# SYSCTRL_PADCONF_WKUP register map
Vendor: Texas Instruments
Peripheral module from a debugger description file (folder omap4430).
Registers are 32-bit, access per field, reset 0x0 unless marked. A register's access mark holds for its fields unless they carry their own. Offsets are as the file gives them; lines under a group give offsets from that group; [hi:lo] are bit positions; {n}, {i} and the like mark numbered series; 'fields as' and 'values as' point back to an identical list; <NAME> marks a mode.

## SYSCTRL_PADCONF_WKUP
0x00 CONTROL_PADCONF_WKUP_REVISION ro reset not defined — Control module revision identifier Access conditions. Read: unrestricted, Write: unrestricted
  [31:0] REVISION — IP Revision
0x04 CONTROL_PADCONF_WKUP_HWINFO ro — Information about the IP module hardware configuration that is, typically the module HDL generics (if any). Access conditions. Read: unrestricted, Write: unrestricted
  [31:0] IP_HWINFO — IP-module dependent
0x10 CONTROL_PADCONF_WKUP_SYSCONFIG reset 0x8 — Access conditions. Read: unrestricted, Write: unrestricted
  [3:2] IP_SYSCONFIG_IDLEMODE rw — Select the local clock-gating strategy0x2,0x3: Clock is automatically gated when there is no access to the Control Module through L4-interconnect .
    0=Clock is manually gated; 1=Clock is manually enabled
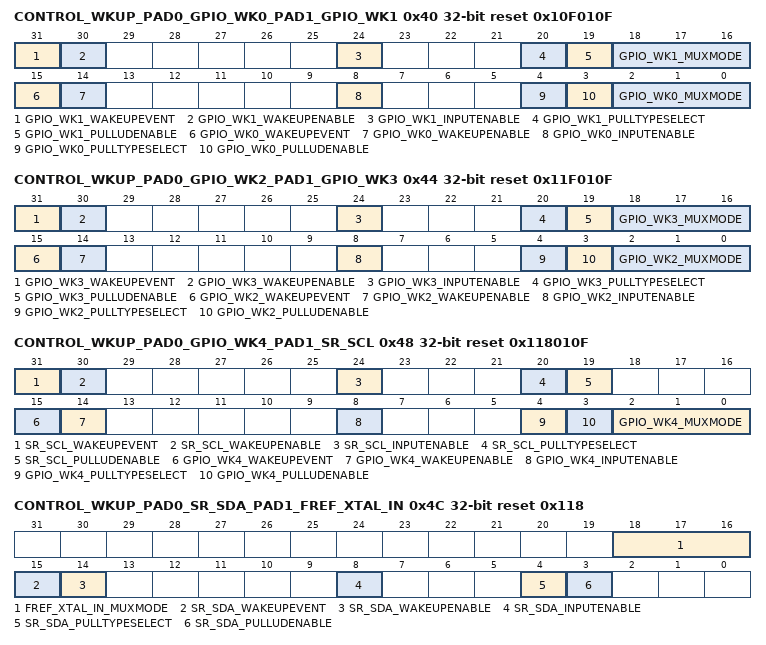
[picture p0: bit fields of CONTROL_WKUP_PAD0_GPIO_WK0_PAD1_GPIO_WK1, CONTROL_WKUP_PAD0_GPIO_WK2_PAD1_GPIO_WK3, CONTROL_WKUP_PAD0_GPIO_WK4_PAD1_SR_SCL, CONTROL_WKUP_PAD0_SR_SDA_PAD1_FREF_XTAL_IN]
0x40 CONTROL_WKUP_PAD0_GPIO_WK0_PAD1_GPIO_WK1 reset 0x10F010F — Register control for Pads gpio_wk0 and gpio_wk1 Access conditions. Read: unrestricted, Write: unrestricted
  [31] GPIO_WK1_WAKEUPEVENT ro — Pad_x wake-up event status latched in the IO
    0=GPIO_WK1_WAKEUPEVENT_0_r (No wake-up event occurred); 1=GPIO_WK1_WAKEUPEVENT_1_r (A wake-up event occurred)
  [30] GPIO_WK1_WAKEUPENABLE rw — Input pad wake-up enable (and OFF mode input enable value)
    0=wake-up detection is disabled; 1=wake-up detection is enabled
  [24] GPIO_WK1_INPUTENABLE rw — Input enable value for pad gpio_wk1
    0=Input buffer of I/O cell is disabled; 1=Input buffer of I/O cell is enabled
  [20] GPIO_WK1_PULLTYPESELECT rw — pullup/down selection for pad gpio_wk1
    0=pulldown selected; 1=pullup selected
  [19] GPIO_WK1_PULLUDENABLE rw — pullup/down enable for pad gpio_wk1
    0=pullup/down disabled; 1=pullup/down enabled
  [18:16] GPIO_WK1_MUXMODE rw — Functional multiplexing selection for pad gpio_wk1
    3=Select gpio_wk1; 6=Select hw_dbg2; 7=Select safe_mode
  [15] GPIO_WK0_WAKEUPEVENT ro — Pad_x wake-up event status latched in the IO
    0=GPIO_WK0_WAKEUPEVENT_0_r (No wake-up event occurred); 1=GPIO_WK0_WAKEUPEVENT_1_r (A wake-up event occurred)
  [14] GPIO_WK0_WAKEUPENABLE rw — Input pad wake-up enable (and OFF mode input enable value)
    values as GPIO_WK1_WAKEUPENABLE
  [8] GPIO_WK0_INPUTENABLE rw — Input enable value for pad gpio_wk0
    values as GPIO_WK1_INPUTENABLE
  [4] GPIO_WK0_PULLTYPESELECT rw — pullup/down selection for pad gpio_wk0
    0=pulldown selected; 1=pullup selected
  [3] GPIO_WK0_PULLUDENABLE rw — pullup/down enable for pad gpio_wk0
    0=pullup/down disabled; 1=pullup/down enabled
  [2:0] GPIO_WK0_MUXMODE rw — Functional multiplexing selection for pad gpio_wk0
    3=Select gpio_wk0; 6=Select hw_dbg1; 7=Select safe_mode
0x44 CONTROL_WKUP_PAD0_GPIO_WK2_PAD1_GPIO_WK3 reset 0x11F010F — Register control for Pads gpio_wk2 and gpio_wk3 Access conditions. Read: unrestricted, Write: unrestricted
  [31] GPIO_WK3_WAKEUPEVENT ro — Pad_x wake-up event status latched in the IO
    0=GPIO_WK3_WAKEUPEVENT_0_r (No wake-up event occurred); 1=GPIO_WK3_WAKEUPEVENT_1_r (A wake-up event occurred)
  [30] GPIO_WK3_WAKEUPENABLE rw — Input pad wake-up enable (and OFF mode input enable value)
    values as CONTROL_WKUP_PAD0_GPIO_WK0_PAD1_GPIO_WK1.GPIO_WK1_WAKEUPENABLE
  [24] GPIO_WK3_INPUTENABLE rw — Input enable value for pad gpio_wk3
    values as CONTROL_WKUP_PAD0_GPIO_WK0_PAD1_GPIO_WK1.GPIO_WK1_INPUTENABLE
  [20] GPIO_WK3_PULLTYPESELECT rw — pullup/down selection for pad gpio_wk3
    0=pulldown selected; 1=pullup selected
  [19] GPIO_WK3_PULLUDENABLE rw — pullup/down enable for pad gpio_wk3
    0=pullup/down disabled; 1=pullup/down enabled
  [18:16] GPIO_WK3_MUXMODE rw — Functional multiplexing selection for pad gpio_wk3
    3=Select gpio_wk3; 6=Select hw_dbg4; 7=Select safe_mode
  [15] GPIO_WK2_WAKEUPEVENT ro — Pad_x wake-up event status latched in the IO
    0=GPIO_WK2_WAKEUPEVENT_0_r (No wake-up event occurred); 1=GPIO_WK2_WAKEUPEVENT_1_r (A wake-up event occurred)
  [14] GPIO_WK2_WAKEUPENABLE rw — Input pad wake-up enable (and OFF mode input enable value)
    values as CONTROL_WKUP_PAD0_GPIO_WK0_PAD1_GPIO_WK1.GPIO_WK1_WAKEUPENABLE
  [8] GPIO_WK2_INPUTENABLE rw — Input enable value for pad gpio_wk2
    values as CONTROL_WKUP_PAD0_GPIO_WK0_PAD1_GPIO_WK1.GPIO_WK1_INPUTENABLE
  [4] GPIO_WK2_PULLTYPESELECT rw — pullup/down selection for pad gpio_wk2
    0=pulldown selected; 1=pullup selected
  [3] GPIO_WK2_PULLUDENABLE rw — pullup/down enable for pad gpio_wk2
    0=pullup/down disabled; 1=pullup/down enabled
  [2:0] GPIO_WK2_MUXMODE rw — Functional multiplexing selection for pad gpio_wk2
    3=Select gpio_wk2; 6=Select hw_dbg3; 7=Select safe_mode
0x48 CONTROL_WKUP_PAD0_GPIO_WK4_PAD1_SR_SCL reset 0x118010F — Register control for Pads gpio_wk4 and sr_scl Access conditions. Read: unrestricted, Write: unrestricted
  [31] SR_SCL_WAKEUPEVENT ro — Pad_x wake-up event status latched in the IO
    0=SR_SCL_WAKEUPEVENT_0_r (No wake-up event occurred); 1=SR_SCL_WAKEUPEVENT_1_r (A wake-up event occurred)
  [30] SR_SCL_WAKEUPENABLE rw — Input pad wake-up enable (and OFF mode input enable value)
    values as CONTROL_WKUP_PAD0_GPIO_WK0_PAD1_GPIO_WK1.GPIO_WK1_WAKEUPENABLE
  [24] SR_SCL_INPUTENABLE rw — Input enable value for pad sr_scl
    values as CONTROL_WKUP_PAD0_GPIO_WK0_PAD1_GPIO_WK1.GPIO_WK1_INPUTENABLE
  [20] SR_SCL_PULLTYPESELECT rw — pullup/down selection for pad sr_scl
    0=pulldown selected; 1=pullup selected
  [19] SR_SCL_PULLUDENABLE rw — pullup/down enable for pad sr_scl
    0=pullup/down disabled; 1=pullup/down enabled
  [15] GPIO_WK4_WAKEUPEVENT ro — Pad_x wake-up event status latched in the IO
    0=GPIO_WK4_WAKEUPEVENT_0_r (No wake-up event occurred); 1=GPIO_WK4_WAKEUPEVENT_1_r (A wake-up event occurred)
  [14] GPIO_WK4_WAKEUPENABLE rw — Input pad wake-up enable (and OFF mode input enable value)
    values as CONTROL_WKUP_PAD0_GPIO_WK0_PAD1_GPIO_WK1.GPIO_WK1_WAKEUPENABLE
  [8] GPIO_WK4_INPUTENABLE rw — Input enable value for pad gpio_wk4
    values as CONTROL_WKUP_PAD0_GPIO_WK0_PAD1_GPIO_WK1.GPIO_WK1_INPUTENABLE
  [4] GPIO_WK4_PULLTYPESELECT rw — pullup/down selection for pad gpio_wk4
    0=pulldown selected; 1=pullup selected
  [3] GPIO_WK4_PULLUDENABLE rw — pullup/down enable for pad gpio_wk4
    0=pullup/down disabled; 1=pullup/down enabled
  [2:0] GPIO_WK4_MUXMODE rw — Functional multiplexing selection for pad gpio_wk4
    3=Select gpio_wk4; 6=Select hw_dbg5; 7=Select safe_mode
0x4C CONTROL_WKUP_PAD0_SR_SDA_PAD1_FREF_XTAL_IN reset 0x118 — Register control for Pads sr_sda and fref_xtal_in Access conditions. Read: unrestricted, Write: unrestricted
  [18:16] FREF_XTAL_IN_MUXMODE rw — Functional multiplexing selection for pad fref_xtal_in
    0=Select fref_xtal_in; 4=Select c2c_wakereqin
  [15] SR_SDA_WAKEUPEVENT ro — Pad_x wake-up event status latched in the IO
    0=SR_SDA_WAKEUPEVENT_0_r (No wake-up event occurred); 1=SR_SDA_WAKEUPEVENT_1_r (A wake-up event occurred)
  [14] SR_SDA_WAKEUPENABLE rw — Input pad wake-up enable (and OFF mode input enable value)
    values as CONTROL_WKUP_PAD0_GPIO_WK0_PAD1_GPIO_WK1.GPIO_WK1_WAKEUPENABLE
  [8] SR_SDA_INPUTENABLE rw — Input enable value for pad sr_sda
    values as CONTROL_WKUP_PAD0_GPIO_WK0_PAD1_GPIO_WK1.GPIO_WK1_INPUTENABLE
  [4] SR_SDA_PULLTYPESELECT rw — pullup/down selection for pad sr_sda
    0=pulldown selected; 1=pullup selected
  [3] SR_SDA_PULLUDENABLE rw — pullup/down enable for pad sr_sda
    0=pullup/down disabled; 1=pullup/down enabled
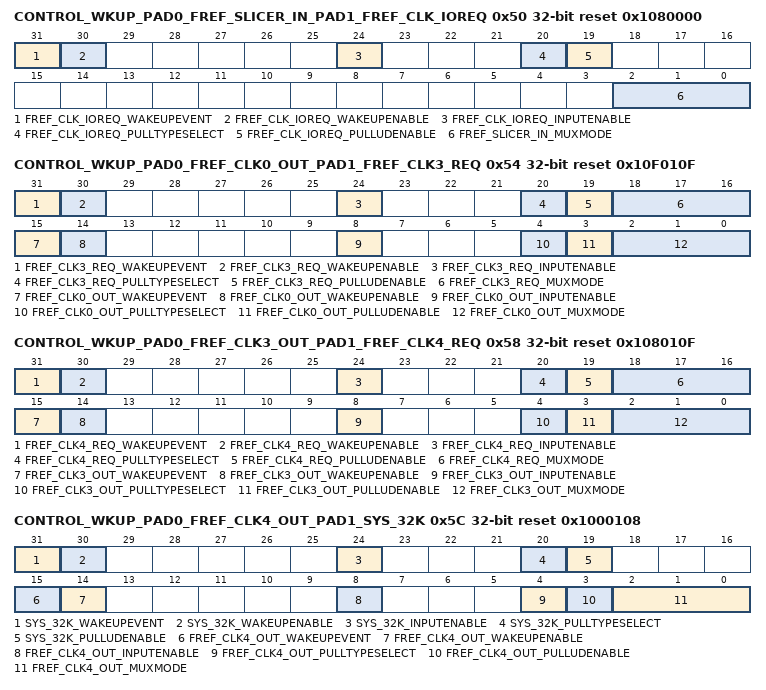
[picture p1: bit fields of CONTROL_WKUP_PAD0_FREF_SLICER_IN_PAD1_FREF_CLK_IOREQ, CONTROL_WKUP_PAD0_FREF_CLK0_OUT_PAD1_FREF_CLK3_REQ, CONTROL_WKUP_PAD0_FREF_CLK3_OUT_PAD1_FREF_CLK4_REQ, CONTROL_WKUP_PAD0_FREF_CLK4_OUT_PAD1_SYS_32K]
0x50 CONTROL_WKUP_PAD0_FREF_SLICER_IN_PAD1_FREF_CLK_IOREQ reset 0x1080000 — Register control for Pads fref_slicer_in and fref_clk_ioreq Access conditions. Read: unrestricted, Write: unrestricted
  [31] FREF_CLK_IOREQ_WAKEUPEVENT ro — Pad_x wake-up event status latched in the IO
    0=FREF_CLK_IOREQ_WAKEUPEVENT_0_r (No wake-up event occurred); 1=FREF_CLK_IOREQ_WAKEUPEVENT_1_r (A wake-up event occurred)
  [30] FREF_CLK_IOREQ_WAKEUPENABLE rw — Input pad wake-up enable (and OFF mode input enable value)
    values as CONTROL_WKUP_PAD0_GPIO_WK0_PAD1_GPIO_WK1.GPIO_WK1_WAKEUPENABLE
  [24] FREF_CLK_IOREQ_INPUTENABLE rw — Input enable value for pad fref_clk_ioreq
    values as CONTROL_WKUP_PAD0_GPIO_WK0_PAD1_GPIO_WK1.GPIO_WK1_INPUTENABLE
  [20] FREF_CLK_IOREQ_PULLTYPESELECT rw — pullup/down selection for pad fref_clk_ioreq
    0=pulldown selected; 1=pullup selected
  [19] FREF_CLK_IOREQ_PULLUDENABLE rw — pullup/down enable for pad fref_clk_ioreq
    0=pullup/down disabled; 1=pullup/down enabled
  [2:0] FREF_SLICER_IN_MUXMODE rw — Functional multiplexing selection for pad fref_slicer_in
    0=Select fref_slicer_in; 3=Select gpi_wk5; 4=Select c2c_wakereqin; 7=Select safe_mode
0x54 CONTROL_WKUP_PAD0_FREF_CLK0_OUT_PAD1_FREF_CLK3_REQ reset 0x10F010F — Register control for Pads fref_clk0_out and fref_clk3_req Access conditions. Read: unrestricted, Write: unrestricted
  [31] FREF_CLK3_REQ_WAKEUPEVENT ro — Pad_x wake-up event status latched in the IO
    0=FREF_CLK3_REQ_WAKEUPEVENT_0_r (No wake-up event occurred); 1=FREF_CLK3_REQ_WAKEUPEVENT_1_r (A wake-up event occurred)
  [30] FREF_CLK3_REQ_WAKEUPENABLE rw — Input pad wake-up enable (and OFF mode input enable value)
    values as CONTROL_WKUP_PAD0_GPIO_WK0_PAD1_GPIO_WK1.GPIO_WK1_WAKEUPENABLE
  [24] FREF_CLK3_REQ_INPUTENABLE rw — Input enable value for pad fref_clk3_req
    values as CONTROL_WKUP_PAD0_GPIO_WK0_PAD1_GPIO_WK1.GPIO_WK1_INPUTENABLE
  [20] FREF_CLK3_REQ_PULLTYPESELECT rw — pullup/down selection for pad fref_clk3_req
    0=pulldown selected; 1=pullup selected
  [19] FREF_CLK3_REQ_PULLUDENABLE rw — pullup/down enable for pad fref_clk3_req
    0=pullup/down disabled; 1=pullup/down enabled
  [18:16] FREF_CLK3_REQ_MUXMODE rw — Functional multiplexing selection for pad fref_clk3_req
    0=Select fref_clk3_req; 1=Select fref_clk1_req; 3=Select gpio_wk30; 4=Select c2c_wakereqin; 5=Select sdmmc2_dat4; 6=Select hw_dbg7; 7=Select safe_mode
  [15] FREF_CLK0_OUT_WAKEUPEVENT ro — Pad_x wake-up event status latched in the IO
    0=FREF_CLK0_OUT_WAKEUPEVENT_0_r (No wake-up event occurred); 1=FREF_CLK0_OUT_WAKEUPEVENT_1_r (A wake-up event occurred)
  [14] FREF_CLK0_OUT_WAKEUPENABLE rw — Input pad wake-up enable (and OFF mode input enable value)
    values as CONTROL_WKUP_PAD0_GPIO_WK0_PAD1_GPIO_WK1.GPIO_WK1_WAKEUPENABLE
  [8] FREF_CLK0_OUT_INPUTENABLE rw — Input enable value for pad fref_clk0_out
    values as CONTROL_WKUP_PAD0_GPIO_WK0_PAD1_GPIO_WK1.GPIO_WK1_INPUTENABLE
  [4] FREF_CLK0_OUT_PULLTYPESELECT rw — pullup/down selection for pad fref_clk0_out
    0=pulldown selected; 1=pullup selected
  [3] FREF_CLK0_OUT_PULLUDENABLE rw — pullup/down enable for pad fref_clk0_out
    0=pullup/down disabled; 1=pullup/down enabled
  [2:0] FREF_CLK0_OUT_MUXMODE rw — Functional multiplexing selection for pad fref_clk0_out
    0=Select fref_clk0_out; 1=Select fref_clk1_req; 3=Select gpio_wk6; 5=Select sdmmc2_dat7; 6=Select hw_dbg6; 7=Select safe_mode
0x58 CONTROL_WKUP_PAD0_FREF_CLK3_OUT_PAD1_FREF_CLK4_REQ reset 0x108010F — Register control for Pads fref_clk3_out and fref_clk4_req Access conditions. Read: unrestricted, Write: unrestricted
  [31] FREF_CLK4_REQ_WAKEUPEVENT ro — Pad_x wake-up event status latched in the IO
    0=FREF_CLK4_REQ_WAKEUPEVENT_0_r (No wake-up event occurred); 1=FREF_CLK4_REQ_WAKEUPEVENT_1_r (A wake-up event occurred)
  [30] FREF_CLK4_REQ_WAKEUPENABLE rw — Input pad wake-up enable (and OFF mode input enable value)
    values as CONTROL_WKUP_PAD0_GPIO_WK0_PAD1_GPIO_WK1.GPIO_WK1_WAKEUPENABLE
  [24] FREF_CLK4_REQ_INPUTENABLE rw — Input enable value for pad fref_clk4_req
    values as CONTROL_WKUP_PAD0_GPIO_WK0_PAD1_GPIO_WK1.GPIO_WK1_INPUTENABLE
  [20] FREF_CLK4_REQ_PULLTYPESELECT rw — pullup/down selection for pad fref_clk4_req
    0=pulldown selected; 1=pullup selected
  [19] FREF_CLK4_REQ_PULLUDENABLE rw — pullup/down enable for pad fref_clk4_req
    0=pullup/down disabled; 1=pullup/down enabled
  [18:16] FREF_CLK4_REQ_MUXMODE rw — Functional multiplexing selection for pad fref_clk4_req
    0=Select fref_clk4_req; 1=Select fref_clk5_out; 3=Select gpio_wk7; 5=Select sdmmc2_dat6; 6=Select hw_dbg9
  [15] FREF_CLK3_OUT_WAKEUPEVENT ro — Pad_x wake-up event status latched in the IO
    0=FREF_CLK3_OUT_WAKEUPEVENT_0_r (No wake-up event occurred); 1=FREF_CLK3_OUT_WAKEUPEVENT_1_r (A wake-up event occurred)
  [14] FREF_CLK3_OUT_WAKEUPENABLE rw — Input pad wake-up enable (and OFF mode input enable value)
    values as CONTROL_WKUP_PAD0_GPIO_WK0_PAD1_GPIO_WK1.GPIO_WK1_WAKEUPENABLE
  [8] FREF_CLK3_OUT_INPUTENABLE rw — Input enable value for pad fref_clk3_out
    values as CONTROL_WKUP_PAD0_GPIO_WK0_PAD1_GPIO_WK1.GPIO_WK1_INPUTENABLE
  [4] FREF_CLK3_OUT_PULLTYPESELECT rw — pullup/down selection for pad fref_clk3_out
    0=pulldown selected; 1=pullup selected
  [3] FREF_CLK3_OUT_PULLUDENABLE rw — pullup/down enable for pad fref_clk3_out
    0=pullup/down disabled; 1=pullup/down enabled
  [2:0] FREF_CLK3_OUT_MUXMODE rw — Functional multiplexing selection for pad fref_clk3_out
    0=Select fref_clk3_out; 1=Select fref_clk2_req; 3=Select gpio_wk31; 4=Select c2c_wakereqout; 5=Select sdmmc2_dat5; 6=Select hw_dbg8; 7=Select safe_mode
0x5C CONTROL_WKUP_PAD0_FREF_CLK4_OUT_PAD1_SYS_32K reset 0x1000108 — Register control for Pads fref_clk4_out and sys_32k Access conditions. Read: unrestricted, Write: unrestricted
  [31] SYS_32K_WAKEUPEVENT ro — Pad_x wake-up event status latched in the IO
    0=SYS_32K_WAKEUPEVENT_0_r (No wake-up event occurred); 1=SYS_32K_WAKEUPEVENT_1_r (A wake-up event occurred)
  [30] SYS_32K_WAKEUPENABLE rw — Input pad wake-up enable (and OFF mode input enable value)
    values as CONTROL_WKUP_PAD0_GPIO_WK0_PAD1_GPIO_WK1.GPIO_WK1_WAKEUPENABLE
  [24] SYS_32K_INPUTENABLE rw — Input enable value for pad sys_32k
    values as CONTROL_WKUP_PAD0_GPIO_WK0_PAD1_GPIO_WK1.GPIO_WK1_INPUTENABLE
  [20] SYS_32K_PULLTYPESELECT rw — pullup/down selection for pad sys_32k
    0=pulldown selected; 1=pullup selected
  [19] SYS_32K_PULLUDENABLE rw — pullup/down enable for pad sys_32k
    0=pullup/down disabled; 1=pullup/down enabled
  [15] FREF_CLK4_OUT_WAKEUPEVENT ro — Pad_x wake-up event status latched in the IO
    0=FREF_CLK4_OUT_WAKEUPEVENT_0_r (No wake-up event occurred); 1=FREF_CLK4_OUT_WAKEUPEVENT_1_r (A wake-up event occurred)
  [14] FREF_CLK4_OUT_WAKEUPENABLE rw — Input pad wake-up enable (and OFF mode input enable value)
    values as CONTROL_WKUP_PAD0_GPIO_WK0_PAD1_GPIO_WK1.GPIO_WK1_WAKEUPENABLE
  [8] FREF_CLK4_OUT_INPUTENABLE rw — Input enable value for pad fref_clk4_out
    values as CONTROL_WKUP_PAD0_GPIO_WK0_PAD1_GPIO_WK1.GPIO_WK1_INPUTENABLE
  [4] FREF_CLK4_OUT_PULLTYPESELECT rw — pullup/down selection for pad fref_clk4_out
    0=pulldown selected; 1=pullup selected
  [3] FREF_CLK4_OUT_PULLUDENABLE rw — pullup/down enable for pad fref_clk4_out
    0=pullup/down disabled; 1=pullup/down enabled
  [2:0] FREF_CLK4_OUT_MUXMODE rw — Functional multiplexing selection for pad fref_clk4_out
    0=Select fref_clk4_out; 3=Select gpio_wk8; 6=Select hw_dbg10
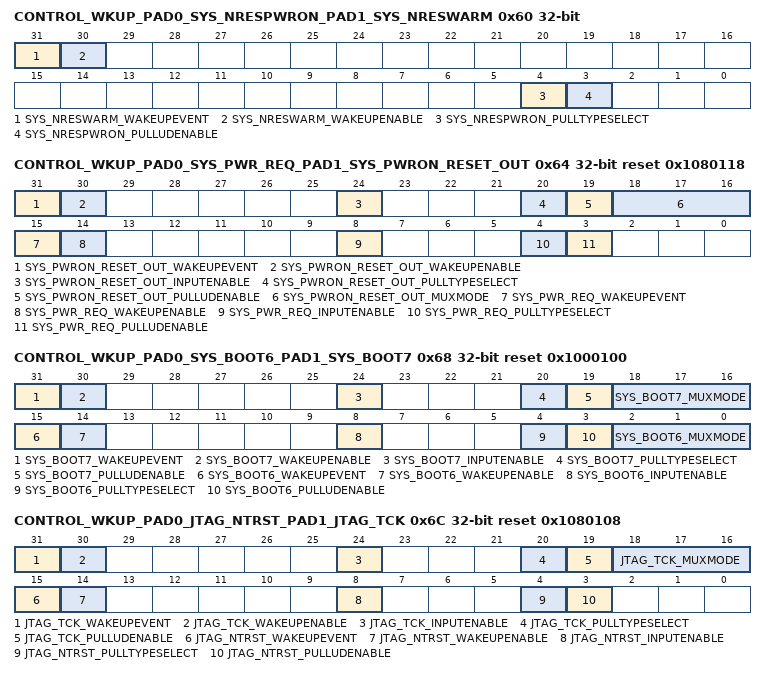
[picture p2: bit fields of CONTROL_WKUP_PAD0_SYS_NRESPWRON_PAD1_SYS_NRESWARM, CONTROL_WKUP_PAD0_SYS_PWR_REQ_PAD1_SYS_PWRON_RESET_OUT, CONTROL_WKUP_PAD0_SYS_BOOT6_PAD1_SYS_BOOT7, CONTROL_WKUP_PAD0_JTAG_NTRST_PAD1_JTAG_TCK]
0x60 CONTROL_WKUP_PAD0_SYS_NRESPWRON_PAD1_SYS_NRESWARM — Register control for Pads sys_nrespwron and sys_nreswarm Access conditions. Read: unrestricted, Write: unrestricted
  [31] SYS_NRESWARM_WAKEUPEVENT ro — Pad_x wake-up event status latched in the IO
    0=SYS_NRESWARM_WAKEUPEVENT_0_r (No wake-up event occurred); 1=SYS_NRESWARM_WAKEUPEVENT_1_r (A wake-up event occurred)
  [30] SYS_NRESWARM_WAKEUPENABLE rw — Input pad wake-up enable (and OFF mode input enable value)
    values as CONTROL_WKUP_PAD0_GPIO_WK0_PAD1_GPIO_WK1.GPIO_WK1_WAKEUPENABLE
  [4] SYS_NRESPWRON_PULLTYPESELECT rw — pullup/down selection for pad sys_nrespwron
    0=pulldown selected; 1=pullup selected
  [3] SYS_NRESPWRON_PULLUDENABLE rw — pullup/down enable for pad sys_nrespwron
    0=pullup/down disabled; 1=pullup/down enabled
0x64 CONTROL_WKUP_PAD0_SYS_PWR_REQ_PAD1_SYS_PWRON_RESET_OUT reset 0x1080118 — Register control for Pads sys_pwr_req and sys_pwron_reset_out Access conditions. Read: unrestricted, Write: unrestricted
  [31] SYS_PWRON_RESET_OUT_WAKEUPEVENT ro — Pad_x wake-up event status latched in the IO
    0=SYS_PWRON_RESET_OUT_WAKEUPEVENT_0_r (No wake-up event occurred); 1=SYS_PWRON_RESET_OUT_WAKEUPEVENT_1_r (A wake-up event occurred)
  [30] SYS_PWRON_RESET_OUT_WAKEUPENABLE rw — Input pad wake-up enable (and OFF mode input enable value)
    values as CONTROL_WKUP_PAD0_GPIO_WK0_PAD1_GPIO_WK1.GPIO_WK1_WAKEUPENABLE
  [24] SYS_PWRON_RESET_OUT_INPUTENABLE rw — Input enable value for pad sys_pwron_reset_out
    values as CONTROL_WKUP_PAD0_GPIO_WK0_PAD1_GPIO_WK1.GPIO_WK1_INPUTENABLE
  [20] SYS_PWRON_RESET_OUT_PULLTYPESELECT rw — pullup/down selection for pad sys_pwron_reset_out
    0=pulldown selected; 1=pullup selected
  [19] SYS_PWRON_RESET_OUT_PULLUDENABLE rw — pullup/down enable for pad sys_pwron_reset_out
    0=pullup/down disabled; 1=pullup/down enabled
  [18:16] SYS_PWRON_RESET_OUT_MUXMODE rw — Functional multiplexing selection for pad sys_pwron_reset_out
    0=Select sys_pwron_reset_out; 3=Select gpio_wk29; 6=SYS_PWRON_ RESET_OUT_MUXMODE_6 (Select hw_dbg11)
  [15] SYS_PWR_REQ_WAKEUPEVENT ro — Pad_x wake-up event status latched in the IO
    0=SYS_PWR_REQ_WAKEUPEVENT_0_r (No wake-up event occurred); 1=SYS_PWR_REQ_WAKEUPEVENT_1_r (A wake-up event occurred)
  [14] SYS_PWR_REQ_WAKEUPENABLE rw — Input pad wake-up enable (and OFF mode input enable value)
    values as CONTROL_WKUP_PAD0_GPIO_WK0_PAD1_GPIO_WK1.GPIO_WK1_WAKEUPENABLE
  [8] SYS_PWR_REQ_INPUTENABLE rw — Input enable value for pad sys_pwr_req
    values as CONTROL_WKUP_PAD0_GPIO_WK0_PAD1_GPIO_WK1.GPIO_WK1_INPUTENABLE
  [4] SYS_PWR_REQ_PULLTYPESELECT rw — pullup/down selection for pad sys_pwr_req
    0=pulldown selected; 1=pullup selected
  [3] SYS_PWR_REQ_PULLUDENABLE rw — pullup/down enable for pad sys_pwr_req
    0=pullup/down disabled; 1=pullup/down enabled
0x68 CONTROL_WKUP_PAD0_SYS_BOOT6_PAD1_SYS_BOOT7 reset 0x1000100 — Register control for Pads sys_boot6 and sys_boot7 Access conditions. Read: unrestricted, Write: unrestricted
  [31] SYS_BOOT7_WAKEUPEVENT ro — Pad_x wake-up event status latched in the IO
    0=SYS_BOOT7_WAKEUPEVENT_0_r (No wake-up event occurred); 1=SYS_BOOT7_WAKEUPEVENT_1_r (A wake-up event occurred)
  [30] SYS_BOOT7_WAKEUPENABLE rw — Input pad wake-up enable (and OFF mode input enable value)
    values as CONTROL_WKUP_PAD0_GPIO_WK0_PAD1_GPIO_WK1.GPIO_WK1_WAKEUPENABLE
  [24] SYS_BOOT7_INPUTENABLE rw — Input enable value for pad sys_boot7
    values as CONTROL_WKUP_PAD0_GPIO_WK0_PAD1_GPIO_WK1.GPIO_WK1_INPUTENABLE
  [20] SYS_BOOT7_PULLTYPESELECT rw — pullup/down selection for pad sys_boot7
    0=pulldown selected; 1=pullup selected
  [19] SYS_BOOT7_PULLUDENABLE rw — pullup/down enable for pad sys_boot7
    0=pullup/down disabled; 1=pullup/down enabled
  [18:16] SYS_BOOT7_MUXMODE rw — Functional multiplexing selection for pad sys_boot7
    0=Select sys_boot7; 1=Select dpm_emu19; 3=Select gpio_wk10; 6=Select hw_dbg13; 7=Select safe_mode
  [15] SYS_BOOT6_WAKEUPEVENT ro — Pad_x wake-up event status latched in the IO
    0=SYS_BOOT6_WAKEUPEVENT_0_r (No wake-up event occurred); 1=SYS_BOOT6_WAKEUPEVENT_1_r (A wake-up event occurred)
  [14] SYS_BOOT6_WAKEUPENABLE rw — Input pad wake-up enable (and OFF mode input enable value)
    values as CONTROL_WKUP_PAD0_GPIO_WK0_PAD1_GPIO_WK1.GPIO_WK1_WAKEUPENABLE
  [8] SYS_BOOT6_INPUTENABLE rw — Input enable value for pad sys_boot6
    values as CONTROL_WKUP_PAD0_GPIO_WK0_PAD1_GPIO_WK1.GPIO_WK1_INPUTENABLE
  [4] SYS_BOOT6_PULLTYPESELECT rw — pullup/down selection for pad sys_boot6
    0=pulldown selected; 1=pullup selected
  [3] SYS_BOOT6_PULLUDENABLE rw — pullup/down enable for pad sys_boot6
    0=pullup/down disabled; 1=pullup/down enabled
  [2:0] SYS_BOOT6_MUXMODE rw — Functional multiplexing selection for pad sys_boot6
    0=Select sys_boot6; 1=Select dpm_emu18; 3=Select gpio_wk9; 4=Select c2c_wakereqout; 6=Select hw_dbg12; 7=Select safe_mode
0x6C CONTROL_WKUP_PAD0_JTAG_NTRST_PAD1_JTAG_TCK reset 0x1080108 — Register control for Pads jtag_ntrst and jtag_tck Access conditions. Read: unrestricted, Write: unrestricted
  [31] JTAG_TCK_WAKEUPEVENT ro — Pad_x wake-up event status latched in the IO
    0=JTAG_TCK_WAKEUPEVENT_0_r (No wake-up event occurred); 1=JTAG_TCK_WAKEUPEVENT_1_r (A wake-up event occurred)
  [30] JTAG_TCK_WAKEUPENABLE rw — Input pad wake-up enable (and OFF mode input enable value)
    values as CONTROL_WKUP_PAD0_GPIO_WK0_PAD1_GPIO_WK1.GPIO_WK1_WAKEUPENABLE
  [24] JTAG_TCK_INPUTENABLE rw — Input enable value for pad jtag_tck
    values as CONTROL_WKUP_PAD0_GPIO_WK0_PAD1_GPIO_WK1.GPIO_WK1_INPUTENABLE
  [20] JTAG_TCK_PULLTYPESELECT rw — pullup/down selection for pad jtag_tck
    0=pulldown selected; 1=pullup selected
  [19] JTAG_TCK_PULLUDENABLE rw — pullup/down enable for pad jtag_tck
    0=pullup/down disabled; 1=pullup/down enabled
  [18:16] JTAG_TCK_MUXMODE rw — Functional multiplexing selection for pad jtag_tck
    0=Select jtag_tck; 7=Select safe_mode
  [15] JTAG_NTRST_WAKEUPEVENT ro — Pad_x wake-up event status latched in the IO
    0=JTAG_NTRST_WAKEUPEVENT_0_r (No wake-up event occurred); 1=JTAG_NTRST_WAKEUPEVENT_1_r (A wake-up event occurred)
  [14] JTAG_NTRST_WAKEUPENABLE rw — Input pad wake-up enable (and OFF mode input enable value)
    values as CONTROL_WKUP_PAD0_GPIO_WK0_PAD1_GPIO_WK1.GPIO_WK1_WAKEUPENABLE
  [8] JTAG_NTRST_INPUTENABLE rw — Input enable value for pad jtag_ntrst
    values as CONTROL_WKUP_PAD0_GPIO_WK0_PAD1_GPIO_WK1.GPIO_WK1_INPUTENABLE
  [4] JTAG_NTRST_PULLTYPESELECT rw — pullup/down selection for pad jtag_ntrst
    0=pulldown selected; 1=pullup selected
  [3] JTAG_NTRST_PULLUDENABLE rw — pullup/down enable for pad jtag_ntrst
    0=pullup/down disabled; 1=pullup/down enabled
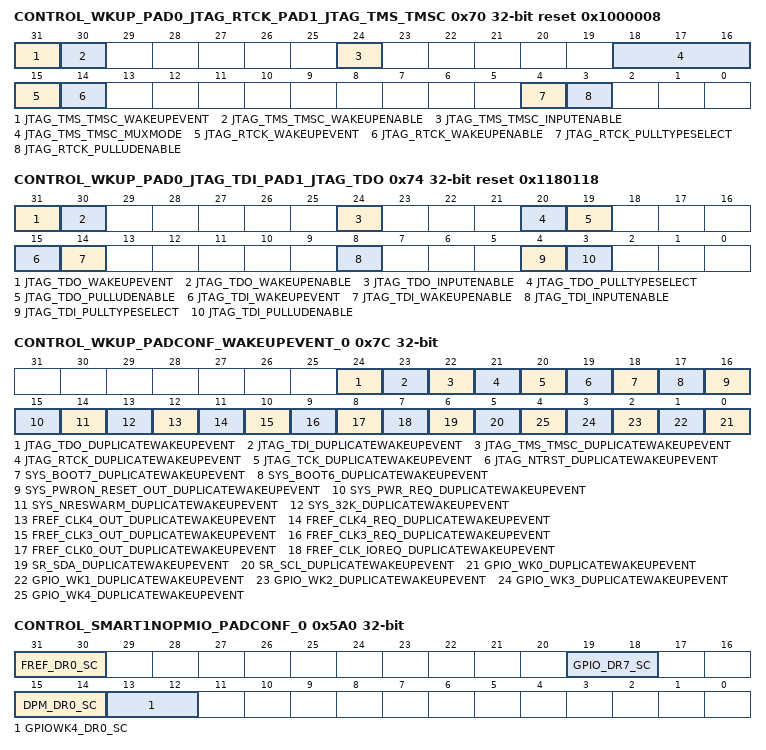
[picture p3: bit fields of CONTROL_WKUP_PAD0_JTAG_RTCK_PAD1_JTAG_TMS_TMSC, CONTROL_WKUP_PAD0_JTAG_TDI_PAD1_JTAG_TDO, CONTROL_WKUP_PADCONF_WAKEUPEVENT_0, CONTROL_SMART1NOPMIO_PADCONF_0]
0x70 CONTROL_WKUP_PAD0_JTAG_RTCK_PAD1_JTAG_TMS_TMSC reset 0x1000008 — Register control for Pads jtag_rtck and jtag_tms_tmsc Access conditions. Read: unrestricted, Write: unrestricted
  [31] JTAG_TMS_TMSC_WAKEUPEVENT ro — Pad_x wake-up event status latched in the IO
    0=JTAG_TMS_TMSC_WAKEUPEVENT_0_r (No wake-up event occurred); 1=JTAG_TMS_TMSC_WAKEUPEVENT_1_r (A wake-up event occurred)
  [30] JTAG_TMS_TMSC_WAKEUPENABLE rw — Input pad wake-up enable (and OFF mode input enable value)
    values as CONTROL_WKUP_PAD0_GPIO_WK0_PAD1_GPIO_WK1.GPIO_WK1_WAKEUPENABLE
  [24] JTAG_TMS_TMSC_INPUTENABLE rw — Input enable value for pad jtag_tms_tmsc
    values as CONTROL_WKUP_PAD0_GPIO_WK0_PAD1_GPIO_WK1.GPIO_WK1_INPUTENABLE
  [18:16] JTAG_TMS_TMSC_MUXMODE rw — Functional multiplexing selection for pad jtag_tms_tmsc
    0=Select jtag_tms_tmsc; 7=Select safe_mode
  [15] JTAG_RTCK_WAKEUPEVENT ro — Pad_x wake-up event status latched in the IO
    0=JTAG_RTCK_WAKEUPEVENT_0_r (No wake-up event occurred); 1=JTAG_RTCK_WAKEUPEVENT_1_r (A wake-up event occurred)
  [14] JTAG_RTCK_WAKEUPENABLE rw — Input pad wake-up enable (and OFF mode input enable value)
    values as CONTROL_WKUP_PAD0_GPIO_WK0_PAD1_GPIO_WK1.GPIO_WK1_WAKEUPENABLE
  [4] JTAG_RTCK_PULLTYPESELECT rw — pullup/down selection for pad jtag_rtck
    0=pulldown selected; 1=pullup selected
  [3] JTAG_RTCK_PULLUDENABLE rw — pullup/down enable for pad jtag_rtck
    0=pullup/down disabled; 1=pullup/down enabled
0x74 CONTROL_WKUP_PAD0_JTAG_TDI_PAD1_JTAG_TDO reset 0x1180118 — Register control for Pads jtag_tdi and jtag_tdo Access conditions. Read: unrestricted, Write: unrestricted
  [31] JTAG_TDO_WAKEUPEVENT ro — Pad_x wake-up event status latched in the IO
    0=JTAG_TDO_WAKEUPEVENT_0_r (No wake-up event occurred); 1=JTAG_TDO_WAKEUPEVENT_1_r (A wake-up event occurred)
  [30] JTAG_TDO_WAKEUPENABLE rw — Input pad wake-up enable (and OFF mode input enable value)
    values as CONTROL_WKUP_PAD0_GPIO_WK0_PAD1_GPIO_WK1.GPIO_WK1_WAKEUPENABLE
  [24] JTAG_TDO_INPUTENABLE rw — Input enable value for pad jtag_tdo
    values as CONTROL_WKUP_PAD0_GPIO_WK0_PAD1_GPIO_WK1.GPIO_WK1_INPUTENABLE
  [20] JTAG_TDO_PULLTYPESELECT rw — pullup/down selection for pad jtag_tdo
    0=pulldown selected; 1=pullup selected
  [19] JTAG_TDO_PULLUDENABLE rw — pullup/down enable for pad jtag_tdo
    0=pullup/down disabled; 1=pullup/down enabled
  [15] JTAG_TDI_WAKEUPEVENT ro — Pad_x wake-up event status latched in the IO
    0=JTAG_TDI_WAKEUPEVENT_0_r (No wake-up event occurred); 1=JTAG_TDI_WAKEUPEVENT_1_r (A wake-up event occurred)
  [14] JTAG_TDI_WAKEUPENABLE rw — Input pad wake-up enable (and OFF mode input enable value)
    values as CONTROL_WKUP_PAD0_GPIO_WK0_PAD1_GPIO_WK1.GPIO_WK1_WAKEUPENABLE
  [8] JTAG_TDI_INPUTENABLE rw — Input enable value for pad jtag_tdi
    values as CONTROL_WKUP_PAD0_GPIO_WK0_PAD1_GPIO_WK1.GPIO_WK1_INPUTENABLE
  [4] JTAG_TDI_PULLTYPESELECT rw — pullup/down selection for pad jtag_tdi
    0=pulldown selected; 1=pullup selected
  [3] JTAG_TDI_PULLUDENABLE rw — pullup/down enable for pad jtag_tdi
    0=pullup/down disabled; 1=pullup/down enabled
0x7C CONTROL_WKUP_PADCONF_WAKEUPEVENT_0 ro — Access conditions. Read: unrestricted, Write: unrestricted
  [24] JTAG_TDO_DUPLICATEWAKEUPEVENT — Wake-up event status latched in the I/O for pad jtag_tdo
    0=JTAG_TDO_DUPLICATEWAKEUPEVENT_0_r (No wake-up event occurred); 1=JTAG_TDO_DUPLICATEWAKEUPEVENT_1_r (A wake-up event occurred)
  [23] JTAG_TDI_DUPLICATEWAKEUPEVENT — Wake-up event status latched in the I/O for pad jtag_tdi
    0=JTAG_TDI_DUPLICATEWAKEUPEVENT_0_r (No wake-up event occurred); 1=JTAG_TDI_DUPLICATEWAKEUPEVENT_1_r (A wake-up event occurred)
  [22] JTAG_TMS_TMSC_DUPLICATEWAKEUPEVENT — Wake-up event status latched in the I/O for pad jtag_tms_tmsc
    0=JTAG_TMS_TMSC_DUPLICATEWAKEUPEVENT_0_r (No wake-up event occurred); 1=JTAG_TMS_TMSC_DUPLICATEWAKEUPEVENT_1_r (A wake-up event occurred)
  [21] JTAG_RTCK_DUPLICATEWAKEUPEVENT — Wake-up event status latched in the I/O for pad jtag_rtck
    0=JTAG_RTCK_DUPLICATEWAKEUPEVENT_0_r (No wake-up event occurred); 1=JTAG_RTCK_DUPLICATEWAKEUPEVENT_1_r (A wake-up event occurred)
  [20] JTAG_TCK_DUPLICATEWAKEUPEVENT — Wake-up event status latched in the I/O for pad jtag_tck
    0=JTAG_TCK_DUPLICATEWAKEUPEVENT_0_r (No wake-up event occurred); 1=JTAG_TCK_DUPLICATEWAKEUPEVENT_1_r (A wake-up event occurred)
  [19] JTAG_NTRST_DUPLICATEWAKEUPEVENT — Wake-up event status latched in the I/O for pad jtag_ntrst
    0=JTAG_NTRST_DUPLICATEWAKEUPEVENT_0_r (No wake-up event occurred); 1=JTAG_NTRST_DUPLICATEWAKEUPEVENT_1_r (A wake-up event occurred)
  [18] SYS_BOOT7_DUPLICATEWAKEUPEVENT — Wake-up event status latched in the I/O for pad sys_boot7
    0=SYS_BOOT7_DUPLICATEWAKEUPEVENT_0_r (No wake-up event occurred); 1=SYS_BOOT7_DUPLICATEWAKEUPEVENT_1_r (A wake-up event occurred)
  [17] SYS_BOOT6_DUPLICATEWAKEUPEVENT — Wake-up event status latched in the I/O for pad sys_boot6
    0=SYS_BOOT6_DUPLICATEWAKEUPEVENT_0_r (No wake-up event occurred); 1=SYS_BOOT6_DUPLICATEWAKEUPEVENT_1_r (A wake-up event occurred)
  [16] SYS_PWRON_RESET_OUT_DUPLICATEWAKEUPEVENT — Wake-up event status latched in the I/O for pad sys_pwron_reset_out
    0=SYS_PWRON_RESET_OUT_DUPLICATEWAKEUPEVENT_0_r (No wake-up event occurred); 1=SYS_PWRON_RESET_OUT_DUPLICATEWAKEUPEVENT_1_r (A wake-up event occurred)
  [15] SYS_PWR_REQ_DUPLICATEWAKEUPEVENT — Wake-up event status latched in the I/O for pad sys_pwr_req
    0=SYS_PWR_REQ_DUPLICATEWAKEUPEVENT_0_r (No wake-up event occurred); 1=SYS_PWR_REQ_DUPLICATEWAKEUPEVENT_1_r (A wake-up event occurred)
  [14] SYS_NRESWARM_DUPLICATEWAKEUPEVENT — Wake-up event status latched in the I/O for pad sys_nreswarm
    0=SYS_NRESWARM_DUPLICATEWAKEUPEVENT_0_r (No wake-up event occurred); 1=SYS_NRESWARM_DUPLICATEWAKEUPEVENT_1_r (A wake-up event occurred)
  [13] SYS_32K_DUPLICATEWAKEUPEVENT — Wake-up event status latched in the I/O for pad sys_32k
    0=SYS_32K_DUPLICATEWAKEUPEVENT_0_r (No wake-up event occurred); 1=SYS_32K_DUPLICATEWAKEUPEVENT_1_r (A wake-up event occurred)
  [12] FREF_CLK4_OUT_DUPLICATEWAKEUPEVENT — Wake-up event status latched in the I/O for pad fref_clk4_out
    0=FREF_CLK4_OUT_DUPLICATEWAKEUPEVENT_0_r (No wake-up event occurred); 1=FREF_CLK4_OUT_DUPLICATEWAKEUPEVENT_1_r (A wake-up event occurred)
  [11] FREF_CLK4_REQ_DUPLICATEWAKEUPEVENT — Wake-up event status latched in the I/O for pad fref_clk4_req
    0=FREF_CLK4_REQ_DUPLICATEWAKEUPEVENT_0_r (No wake-up event occurred); 1=FREF_CLK4_REQ_DUPLICATEWAKEUPEVENT_1_r (A wake-up event occurred)
  [10] FREF_CLK3_OUT_DUPLICATEWAKEUPEVENT — Wake-up event status latched in the I/O for pad fref_clk3_out
    0=FREF_CLK3_OUT_DUPLICATEWAKEUPEVENT_0_r (No wake-up event occurred); 1=FREF_CLK3_OUT_DUPLICATEWAKEUPEVENT_1_r (A wake-up event occurred)
  [9] FREF_CLK3_REQ_DUPLICATEWAKEUPEVENT — Wake-up event status latched in the I/O for pad fref_clk3_req
    0=FREF_CLK3_REQ_DUPLICATEWAKEUPEVENT_0_r (No wake-up event occurred); 1=FREF_CLK3_REQ_DUPLICATEWAKEUPEVENT_1_r (A wake-up event occurred)
  [8] FREF_CLK0_OUT_DUPLICATEWAKEUPEVENT — Wake-up event status latched in the I/O for pad fref_clk0_out
    0=FREF_CLK0_OUT_DUPLICATEWAKEUPEVENT_0_r (No wake-up event occurred); 1=FREF_CLK0_OUT_DUPLICATEWAKEUPEVENT_1_r (A wake-up event occurred)
  [7] FREF_CLK_IOREQ_DUPLICATEWAKEUPEVENT — Wake-up event status latched in the I/O for pad fref_clk_ioreq
    0=FREF_CLK_IOREQ_DUPLICATEWAKEUPEVENT_0_r (No wake-up event occurred); 1=FREF_CLK_IOREQ_DUPLICATEWAKEUPEVENT_1_r (A wake-up event occurred)
  [6] SR_SDA_DUPLICATEWAKEUPEVENT — Wake-up event status latched in the I/O for pad sr_sda
    0=SR_SDA_DUPLICATEWAKEUPEVENT_0_r (No wake-up event occurred); 1=SR_SDA_DUPLICATEWAKEUPEVENT_1_r (A wake-up event occurred)
  [5] SR_SCL_DUPLICATEWAKEUPEVENT — Wake-up event status latched in the I/O for pad sr_scl
    0=SR_SCL_DUPLICATEWAKEUPEVENT_0_r (No wake-up event occurred); 1=SR_SCL_DUPLICATEWAKEUPEVENT_1_r (A wake-up event occurred)
  [n] GPIO_WK{n}_DUPLICATEWAKEUPEVENT (n=0..4) — Wake-up event status latched in the I/O for pad gpio_wk{n}
    0=GPIO_WK{n}_DUPLICATEWAKEUPEVENT_0_r (No wake-up event occurred); 1=GPIO_WK{n}_DUPLICATEWAKEUPEVENT_1_r (A wake-up event occurred)
0x5A0 CONTROL_SMART1NOPMIO_PADCONF_0 — SMART1 NOPM I/O control 0 Access conditions. Read: unrestricted, Write: unrestricted
  [31:30] FREF_DR0_SC rw — Slew rate control for group fref_dr0 Refer to , section Low Speed I/Os Combined Slew Rate vs TL Length and Load Settings for more details on SR settings.
  [19:18] GPIO_DR7_SC rw — Slew rate control for group gpio_dr7 Refer to , section Low Speed I/Os Combined Slew Rate vs TL Length and Load Settings for more details on SR settings.
  [15:14] DPM_DR0_SC rw — Slew rate control for group dpm_dr0 Refer to , section Low Speed I/Os Combined Slew Rate vs TL Length and Load Settings for more details on SR settings.
  [13:12] GPIOWK4_DR0_SC rw — Slew rate control for group gpiowk4_dr0 Refer to , section Low Speed I/Os Combined Slew Rate vs TL Length and Load Settings for more details on SR settings.
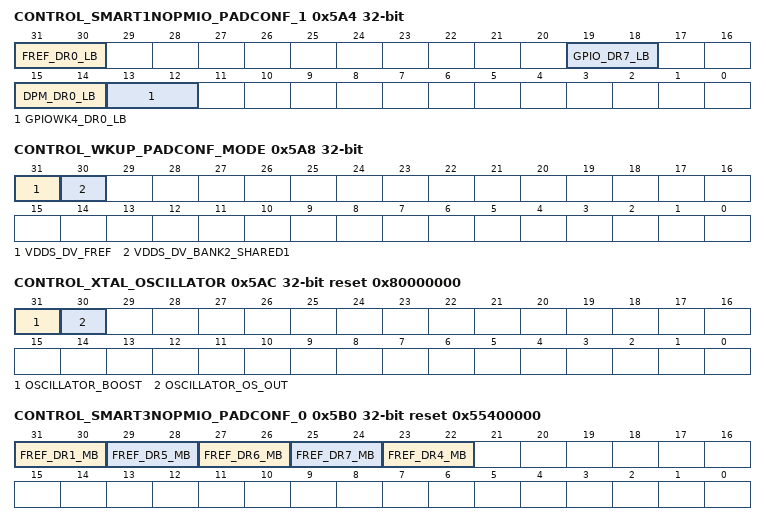
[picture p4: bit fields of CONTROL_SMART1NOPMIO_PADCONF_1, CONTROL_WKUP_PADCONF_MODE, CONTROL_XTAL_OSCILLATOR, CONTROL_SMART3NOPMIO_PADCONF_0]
0x5A4 CONTROL_SMART1NOPMIO_PADCONF_1 — SMART1 NOPM I/O control 1 Access conditions. Read: unrestricted, Write: unrestricted
  [all] fields
    0=TL Length= [2cm-20cm] / Farend cap per TL= [1pF-10pF]; 1=Dual TL Length= [20cm-40cm] / Farend cap per TL= [1pF-10pF]; 2=TL Length = [2cm-20cm] / Farend cap per TL= [10pF-20pF]; 3=Dual TL Length = [20cm-40cm] / Farend cap per TL= [10pF-20pF]
  [31:30] FREF_DR0_LB rw — Load control for group fref_dr0
  [19:18] GPIO_DR7_LB rw — Load control for group gpio_dr7
  [15:14] DPM_DR0_LB rw — Load control for group dpm_dr0
  [13:12] GPIOWK4_DR0_LB rw — Load control for group gpiowk4_dr0
0x5A8 CONTROL_WKUP_PADCONF_MODE — PAD Voltage Mode control Access conditions. Read: unrestricted, Write: unrestricted
  [31] VDDS_DV_FREF rw — PAD Voltage level control for vdds_dv_fref
    0=VDDS = 1.8V; 1=VDDS = 1.2V
  [30] VDDS_DV_BANK2_SHARED1 rw — PAD Voltage level control for vdds_dv_bank2_shared1
    0=VDDS = 1.8V; 1=VDDS = 1.2V
0x5AC CONTROL_XTAL_OSCILLATOR reset 0x80000000 — XTAL OSCILLATOR control Access conditions. Read: unrestricted, Write: unrestricted
  [31] OSCILLATOR_BOOST rw — Fast startup control
    0=Fast startup is disabled; 1=Fast startup is enabled
  [30] OSCILLATOR_OS_OUT ro — Oscillator output
    0=OSCILLATOR_OS_OUT_0_r (low to high transition in BOOST mode); 1=OSCILLATOR_OS_OUT_1_r (BOOST is disabled)
0x5B0 CONTROL_SMART3NOPMIO_PADCONF_0 reset 0x55400000 — SMART3 NOPM IO control 0 Access conditions. Read: unrestricted, Write: unrestricted
  [31:30] FREF_DR1_MB rw — 50-Ω output buffer mode control for group fref_dr1 Refer to 50-Ω output buffer I/Os with combined Mode and Load Settings for more details on mode settings.
  [29:28] FREF_DR5_MB rw — 50-Ω output buffer mode control for group fref_dr5 Refer to 50-Ω output buffer I/Os with combined Mode and Load Settings for more details on mode settings.
  [27:26] FREF_DR6_MB rw — 50-Ω output buffer mode control for group fref_dr6 Refer to 50-Ω output buffer I/Os with combined Mode and Load Settings for more details on mode settings.
  [25:24] FREF_DR7_MB rw — 50-Ω output buffer mode control for group Refer to 50-Ω output buffer I/Os with combined Mode and Load Settings for more details on mode settings.
  [23:22] FREF_DR4_MB rw — 50-Ω output buffer mode control for group fref_dr4 Refer to 50-Ω output buffer I/Os with combined Mode and Load Settings for more details on mode settings.
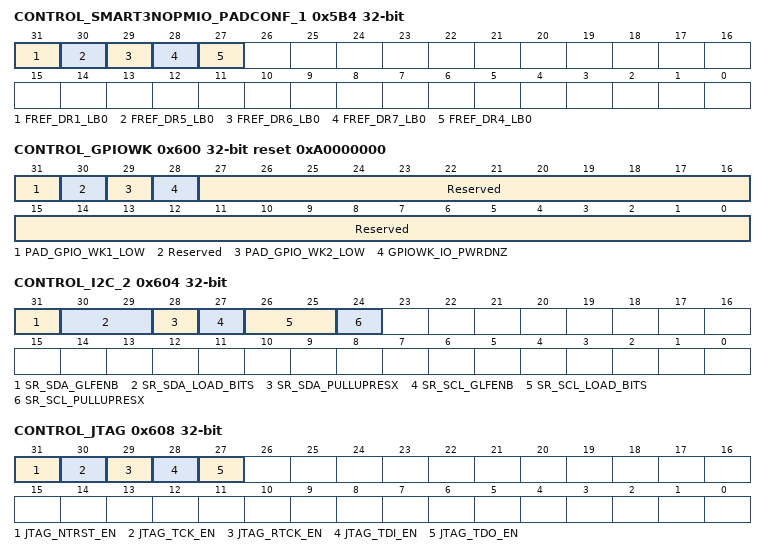
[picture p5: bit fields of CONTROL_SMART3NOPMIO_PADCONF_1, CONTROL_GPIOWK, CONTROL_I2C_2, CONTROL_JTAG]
0x5B4 CONTROL_SMART3NOPMIO_PADCONF_1 — SMART3 NOPM IO control 1 Access conditions. Read: unrestricted, Write: unrestricted
  [31] FREF_DR1_LB0 rw — 50-Ω output buffer load control for group fref_dr1 Refer to 50-Ω output buffer I/Os with combined Mode and Load Settings for more details on mode settings.
  [30] FREF_DR5_LB0 rw — 50-Ω output buffer load control for group fref_dr5 Refer to 50-Ω output buffer I/Os with combined Mode and Load Settings for more details on mode settings.
  [29] FREF_DR6_LB0 rw — 50-Ω output buffer load control for group fref_dr6 Refer to 50-Ω output buffer I/Os with combined Mode and Load Settings for more details on mode settings.
  [28] FREF_DR7_LB0 rw — 50-Ω output buffer load control for group fref_dr7 Refer to 50-Ω output buffer I/Os with combined Mode and Load Settings for more details on mode settings.
  [27] FREF_DR4_LB0 rw — 50-Ω output buffer load control for group fref_dr4 Refer to 50-Ω output buffer I/Os with combined Mode and Load Settings for more details on mode settings.
0x600 CONTROL_GPIOWK access not given reset 0xA0000000 — GPIOWK pads I/O control Access conditions. Read: unrestricted; Write: unrestricted
  [31] PAD_GPIO_WK1_LOW rw — LOW enable for gpio_wk1 PAD
    0=Strong pulldown is disabled; 1=Strong pulldown after reset release
  [30] Reserved — (access RO Rreturns0s)
  [29] PAD_GPIO_WK2_LOW rw — LOW enable for gpio_wk2 PAD
    values as PAD_GPIO_WK1_LOW
  [28] GPIOWK_IO_PWRDNZ rw — PWRDNZ control to gpiowk0-gpiowk2 IOsThis bit is used to protect the gpio_wk0-gpio_wk2 pads associated I/O cell when SIM_VDDS is not stable. .
    0=Software must clear this bit when SIM_VDDS changes; 1=Software must set this bit only when SIM_VDDS is stable
  [27:0] Reserved — (access RO Rreturns0s)
0x604 CONTROL_I2C_2 — I2C pads control 2 Access conditions. Read: unrestricted, Write: unrestricted
  [31] SR_SDA_GLFENB rw — Active_high glitch free operation enable pin for sr i2c receiver
    0=Disable i2c4 glitch free operation; 1=Enable i2c4 glitch free operation
  [30:29] SR_SDA_LOAD_BITS rw — Internal Pull up resistor in Fast or Standard mode /High_speed mode for sr i2c
    0=4.5 kΩ (5-15 pF) / 1.66 kΩ (5-12 pF); 1=2.1 kΩ (15-50 pF) / 920 Ω (12-25 pF); 2=860 Ω (50-150 pF) / 500 Ω (25-50 pF); 3=N.A / 300 Ω (50-80 pF)
  [28] SR_SDA_PULLUPRESX rw — Active_low internal pull_up resistor enabled for sr i2c
    0=Enable Internal Pull up resistor; 1=Disable Internal Pull up resisitor
  [27] SR_SCL_GLFENB rw — Active_high glitch free operation enable pin for sr i2c receiver
    values as SR_SDA_GLFENB
  [26:25] SR_SCL_LOAD_BITS rw — Internal Pull up resistor in Fast or Standard mode /High_speed mode for sr i2c
    values as SR_SDA_LOAD_BITS
  [24] SR_SCL_PULLUPRESX rw — Active_low internal pull_up resistor enabled for sr i2c
    values as SR_SDA_PULLUPRESX
0x608 CONTROL_JTAG — JTAG pads control Access conditions. Read: unrestricted, Write: unrestricted
  [all] fields
    0=Disable bus holder functionality; 1=Enable bus holder functionality
  [31] JTAG_NTRST_EN rw — bus holder enable for jtag_ntrst PAD
  [30] JTAG_TCK_EN rw — bus holder enable for jtag_tck PAD
  [29] JTAG_RTCK_EN rw — bus holder enable for jtag_rtck PAD
  [28] JTAG_TDI_EN rw — bus holder enable for jtag_tdi PAD
  [27] JTAG_TDO_EN rw — bus holder enable for jtag_tdo PAD
0x60C CONTROL_SYS — SYS controls Access conditions. Read: unrestricted, Write: unrestricted
  [31] SYS_NRESWARM_PIPU rw — Pull up enable for sys_nreswarm PAD
    0=Enable pull up; 1=Disable pull up
0x614 CONTROL_WKUP_CONTROL_SPARE_RW rw — Wake-up control spare RW Access conditions. Read: unrestricted, Write: unrestricted
  [31:0] WKUP_CONTROL_SPARE_RW — Wake-up control spare register bits RW
0x618 CONTROL_WKUP_CONTROL_SPARE_R ro — Wake-up control spare R Access conditions. Read: unrestricted, Write: unrestricted
  [31:0] WKUP_CONTROL_SPARE_R — Wake-up control spare register bits R
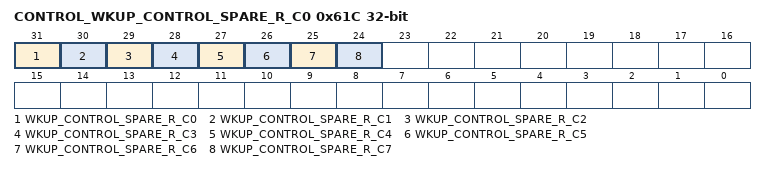
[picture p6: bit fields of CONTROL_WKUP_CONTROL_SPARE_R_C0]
0x61C CONTROL_WKUP_CONTROL_SPARE_R_C0 access not given — Wake-up control spare RC Access conditions. Read: unrestricted, Write: unrestricted
  [31-n] WKUP_CONTROL_SPARE_R_C{n} (n=0..7) — Wake-up control spare register bits RC (access RW (Write 1 to Clear))
{0x61C+4i} CONTROL_WKUP_CONTROL_SPARE_RW{i} rw (i=1..8) — WKUP control spare RW{i} Access conditions. Read: unrestricted, Write: unrestricted
  [31:0] WKUP_CONTROL_SPARE_RW{i} — wkup control spare register bits RW{i}
0x640 CONTROL_WKUP_CONTROL_SPARE_RW9 rw reset 0xFFFFFFFF — WKUP control spare RW9 Access conditions. Read: unrestricted, Write: unrestricted
  [31:0] WKUP_CONTROL_SPARE_RW9 — wkup control spare register bits RW9
0x64C CONTROL_WKUP_CONTROL_SPARE_R1 ro — WKUP control spare R1 Access conditions. Read: unrestricted, Write: unrestricted
  [31:0] WKUP_CONTROL_SPARE_R1 — wkup control spare register bits R1
